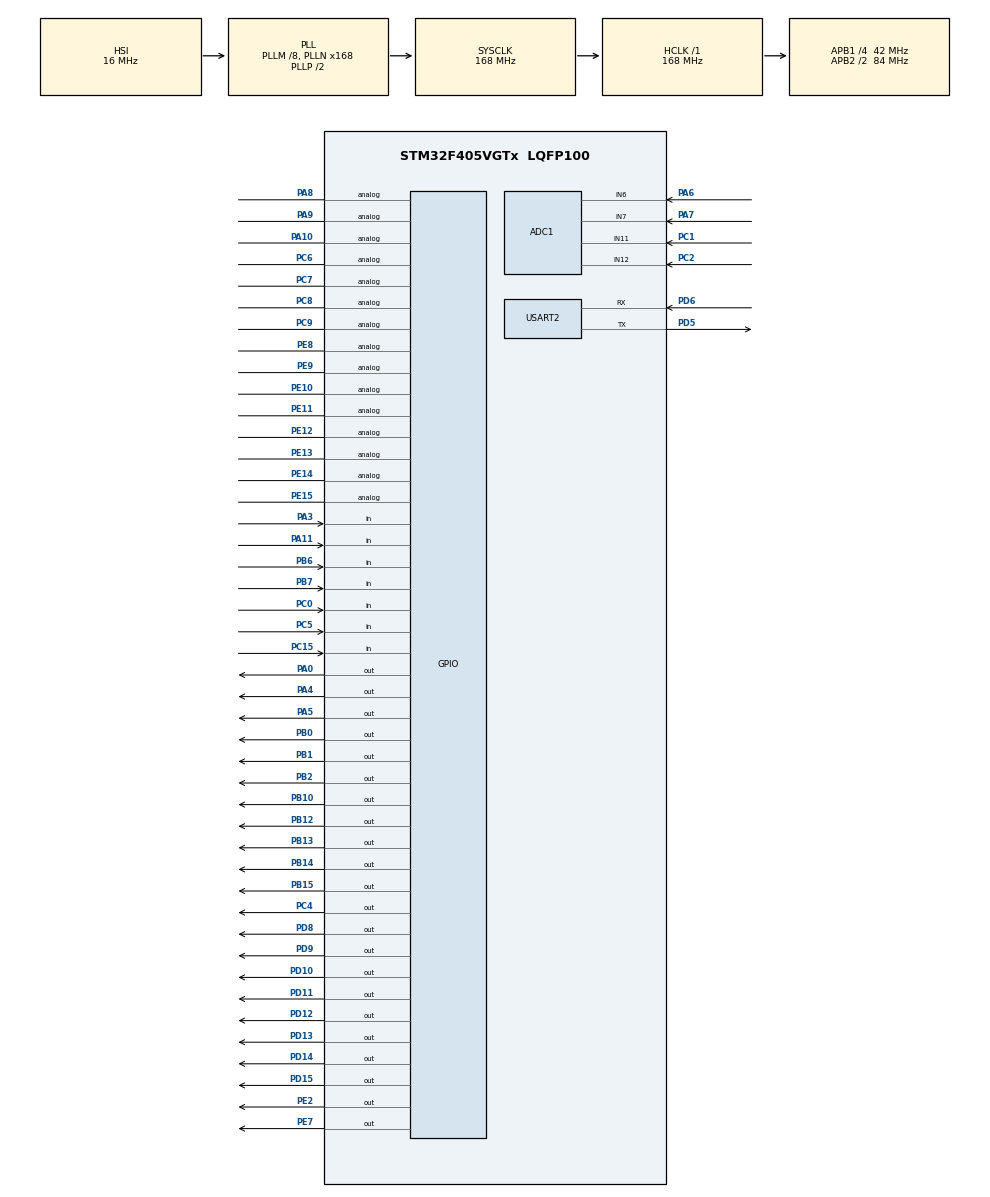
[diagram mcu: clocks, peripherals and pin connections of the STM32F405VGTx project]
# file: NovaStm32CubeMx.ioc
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ADC1.Channel-0\#ChannelRegularConversion=ADC_CHANNEL_11
ADC1.NbrOfConversionFlag=1
ADC1.Rank-0\#ChannelRegularConversion=1
ADC1.SamplingTime-0\#ChannelRegularConversion=ADC_SAMPLETIME_3CYCLES
ADC1.master=1
FREERTOS.Tasks01=defaultTask,24,128,StartDefaultTask,Default,NULL,Dynamic,NULL,NULL
FREERTOS.configENABLE_FPU=1
Mcu.Family=STM32F4
Mcu.Name=STM32F405VGTx
Mcu.Package=LQFP100
NVIC.PriorityGroup=NVIC_PRIORITYGROUP_4
PA0-WKUP.Signal=GPIO_Output
PA1.Signal=EVENTOUT
PA10.Signal=GPIO_Analog
PA11.Signal=GPIO_Input
PA13.Signal=SYS_JTMS-SWDIO
PA14.Signal=SYS_JTCK-SWCLK
PA2.Signal=EVENTOUT
PA3.Signal=GPIO_Input
PA4.Signal=GPIO_Output
PA5.Signal=GPIO_Output
PA6.Signal=ADCx_IN6
PA7.Signal=ADCx_IN7
PA8.Signal=GPIO_Analog
PA9.Signal=GPIO_Analog
PB0.Signal=GPIO_Output
PB1.Signal=GPIO_Output
PB10.Signal=GPIO_Output
PB12.Signal=GPIO_Output
PB13.Signal=GPIO_Output
PB14.Signal=GPIO_Output
PB15.Signal=GPIO_Output
PB2.Signal=GPIO_Output
PB6.Signal=GPIO_Input
PB7.Signal=GPIO_Input
PC0.Signal=GPIO_Input
PC1.Signal=ADCx_IN11
PC15-OSC32_OUT.Signal=GPIO_Input
PC2.Signal=ADCx_IN12
PC4.Signal=GPIO_Output
PC5.Signal=GPIO_Input
PC6.Signal=GPIO_Analog
PC7.Signal=GPIO_Analog
PC8.Signal=GPIO_Analog
PC9.Signal=GPIO_Analog
PD10.Signal=GPIO_Output
PD11.Signal=GPIO_Output
PD12.Signal=GPIO_Output
PD13.Signal=GPIO_Output
PD14.Signal=GPIO_Output
PD15.Signal=GPIO_Output
PD5.Mode=Asynchronous
PD5.Signal=USART2_TX
PD6.Mode=Asynchronous
PD6.Signal=USART2_RX
PD8.Signal=GPIO_Output
PD9.Signal=GPIO_Output
PE10.Signal=GPIO_Analog
PE11.Signal=GPIO_Analog
PE12.Signal=GPIO_Analog
PE13.Signal=GPIO_Analog
PE14.Signal=GPIO_Analog
PE15.Signal=GPIO_Analog
PE2.Signal=GPIO_Output
PE7.Signal=GPIO_Output
PE8.Signal=GPIO_Analog
PE9.Signal=GPIO_Analog
PH0-OSC_IN.Mode=HSE-External-Oscillator
PH0-OSC_IN.Signal=RCC_OSC_IN
PH1-OSC_OUT.Mode=HSE-External-Oscillator
PH1-OSC_OUT.Signal=RCC_OSC_OUT
ProjectManager.HeapSize=0x200
ProjectManager.StackSize=0x400
ProjectManager.TargetToolchain=MDK-ARM V5.27
RCC.48MHZClocksFreq_Value=84000000
RCC.AHBFreq_Value=168000000
RCC.APB1CLKDivider=RCC_HCLK_DIV4
RCC.APB1Freq_Value=42000000
RCC.APB1TimFreq_Value=84000000
RCC.APB2CLKDivider=RCC_HCLK_DIV2
RCC.APB2Freq_Value=84000000
RCC.APB2TimFreq_Value=168000000
RCC.CortexFreq_Value=168000000
RCC.HCLKFreq_Value=168000000
RCC.HSE_VALUE=8000000
RCC.HSI_VALUE=16000000
RCC.LSE_VALUE=32768
RCC.PLLM=8
RCC.PLLN=168
RCC.SYSCLKFreq_VALUE=168000000
RCC.SYSCLKSource=RCC_SYSCLKSOURCE_PLLCLK
RCC.VCOOutputFreq_Value=336000000
SH.ADCx_IN11.0=ADC1_IN11,IN11
SH.ADCx_IN12.0=ADC1_IN12,IN12
SH.ADCx_IN6.0=ADC1_IN6,IN6
SH.ADCx_IN7.0=ADC1_IN7,IN7
USART2.VirtualMode=VM_ASYNC
VP_FREERTOS_VS_CMSIS_V2.Mode=CMSIS_V2
VP_IWDG_VS_IWDG.Mode=IWDG_Activate
board=custom

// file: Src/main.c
/* USER CODE BEGIN Header */
/**
  ******************************************************************************
  * @file           : main.c
  * @brief          : Main program body
  ******************************************************************************
  * @attention
  *
  * <h2><center>&copy; Copyright (c) 2020 STMicroelectronics.
  * All rights reserved.</center></h2>
  *
  * This software component is licensed by ST under BSD 3-Clause license,
  * the "License"; You may not use this file except in compliance with the
  * License. You may obtain a copy of the License at:
  *                        opensource.org/licenses/BSD-3-Clause
  *
  ******************************************************************************
  */
/* USER CODE END Header */

#include "main.h"
#include "cmsis_os.h"
#include "FreeRTOS.h"
#include "Timers.h"
#include "..\MDK-ARM\delay.h"
#include "..\MDK-ARM\24cxx.h"
#include "..\MDK-ARM\keys.h"
#include "..\MDK-ARM\LCD_Display.h"
#include "..\MDK-ARM\userinterface.h"
#include "..\MDK-ARM\PWM.h"
#include "..\MDK-ARM\data.h"
#include "..\MDK-ARM\pwm_timer.h"
#include "..\MDK-ARM\ADCSample.h"
#include "..\MDK-ARM\uart2.h"
#include "stdio.h"
//#include "..\MDK-ARM\font.h"
//#include "..\MDK-ARM\powerON.h"

//typedef StaticTimer_t osStaticTimerDef_t;

/* USER CODE BEGIN PM */
#define STYTESM_POWER_ON HAL_GPIO_WritePin(GPIOA, GPIO_PIN_5, GPIO_PIN_SET)

/* USER CODE END PM */

ADC_HandleTypeDef hadc1;

IWDG_HandleTypeDef hiwdg;

/* Definitions for defaultTask */
osThreadId_t mainTaskTaskHandle;
const osThreadAttr_t mainTask_attributes = {
  .name = "MainTask",
  .priority = (osPriority_t) osPriorityNormal,
  .stack_size = 128 * 4
};

osThreadId_t keyScanTaskTaskHandle;
const osThreadAttr_t keyScanTask_attributes = {
  .name = "keyScanTask",
  .priority = (osPriority_t) osPriorityRealtime,
  .stack_size = 128 * 4
};

/* USER CODE END PV */

void SystemClock_Config(void);
static void MX_GPIO_Init(void);
static void MX_ADC1_Init(void);
static void MX_IWDG_Init(void);
void MainTask(void *argument);
void keyScanTask(void *argument);

u16 ADC_data = 0;
int main(void)
{
    /* MCU Configuration--------------------------------------------------------*/

    /* Reset of all peripherals, Initializes the Flash interface and the Systick. */
    HAL_Init();
    /* Configure the system clock */
    SystemClock_Config();

    /*delay time init */
    //delay_init(168);

    /* Initialize all configured peripherals */
    MX_GPIO_Init();
    HAL_GPIO_WritePin(GPIOD, GPIO_PIN_15, GPIO_PIN_SET);//GPIO_PIN_RESET); Kavo Logo Led
    LED_init(LED_ON);
    LED_control(GREEN_LED);
    for(u16 i = 0;i<1000;i++)
        delay_1_ms();
    STYTESM_POWER_ON;
    //for(u16 i = 0;i<2000;i++)
    //    delay_1_ms();
    LCD_Init();
    LCD_Clear(0XFFFF);
    LCD_BK_1;
    powerOn_displayFunc();

    LED_control(ORANGE_LED);
    LED_init(LED_ON);

    MX_ADC1_Init();
    IIC_Init();
    Keys_Init();
//    LCD_Init();
    PWM_Init();
#if DEBUG_ON
    MX_USART2_UART_Init();
#endif
    for(u16 i = 0;i<1000;i++)
        delay_1_ms();

    LED_control(BLUE_LED);
    for(u16 i = 0;i<2000;i++)
        delay_1_ms();

    //test_get_set_sys_para();
    //fagctory_default_store();
    //ADC_data = AT24CXX_ReadOneByte(4096);
    //EraseAll();
    check_para_is_valid();
    system_para_restore();
    //test_para_store_restore();
    //test_set_get_exposetime();
    //pictureDisplay(20,31,105,30,gImage_kV);
#if 0
    LCD_Clear(0X2965);
    LCD_Clear(0X528A);
    LCD_Clear(0X738E);
    LCD_Clear(0X8C51);
    LCD_Clear(0XBDF7);
    LCD_Clear(0XCE79);
    LCD_Clear(0XE73C);
#endif
//    LCD_Clear(0XFFFF);
//    LCD_BK_1;
//    powerOn_displayFunc();
    LED_init(LED_OFF);
    MainWindowDisplayFunc();

    LED_Control(tooth_position,LED_ON);

    while(HAL_GPIO_ReadPin(GPIOA, GPIO_PIN_11) == 0);//wait for the power key releasing

#if DEBUG_ON

#else
    MX_IWDG_Init();
#endif
    LED_control(GREEN_LED);

    //save the event: power on
    event_Data_Store(POWER_ON);

    //MainWindowDisplayFunc();
    //pictureDisplay(217+15,60,19,30 ,battery4);

   //  test_Event_Data_EEPROM_function();

   //set_voltage_current(1274, 1274);

   get_voltage_current(&pwm_voltage_cali,&pwm_current);
  //Keys_Portinit();
  //Keys_GetPins();
  //test
  //test_read_write_bytes();
  //AT24CXX_Check();

 // pwmSet(PWM_KV_REF, PWM_VOLTAGE_VALUE);
 // pwmSet(PWM_MA_REF, PWM_CURRENT_VALUE);
 // while(1);
 //  while(1)
 // {
 //     ADC_data = Get_Adc(BATTERY_VOLTAGE);
      // AT24CXX_Check();
      //AT24CXX_ReadOneByte(255);
      //test_time();
      //AT24CXX_ReadOneByte(0xAA);
      //test_read_write();
      //delay_us(100);
      //delay_1_ms();
      //delay_1_ms();
      //delay_1_ms();
      //ADC_data = Get_Adc(ADAPTER_VOLTAGE);
      //delay_1_ms();
      //delay_1_ms();
      //delay_1_ms();
      //Keys_Scan();
  //}

  /* Init scheduler */
  system_state = IDLE_STATE;
  WIN = MainWindowDisplay;
  osKernelInitialize();

  /* Create the timer(s) */
  /* creation of myTimer01 */
  //myTimer01Handle = osTimerNew(Callback01, osTimerOnce, NULL, &myTimer01_attributes);
  myTimer02Handle = osTimerNew(Callback02, osTimerPeriodic, NULL, &myTimer02_attributes);

  /* USER CODE BEGIN RTOS_TIMERS */
  /* start timers, add new ones, ... */
  osTimerStart(myTimer02Handle,1);//start timer2, peroid 1 ms
  /* USER CODE END RTOS_TIMERS */

  /* Create the thread(s) */
  /* creation of defaultTask */
  mainTaskTaskHandle = osThreadNew(MainTask, NULL, &mainTask_attributes);
  keyScanTaskTaskHandle = osThreadNew(keyScanTask,NULL,&keyScanTask_attributes);

  /* Start scheduler */
  osKernelStart();

  /* We should never get here as control is now taken by the scheduler */
  /* Infinite loop */
  while (1)
  {

  }
}

void SystemClock_Config(void)
{
  RCC_OscInitTypeDef RCC_OscInitStruct = {0};
  RCC_ClkInitTypeDef RCC_ClkInitStruct = {0};

  /** Configure the main internal regulator output voltage
  */
  __HAL_RCC_PWR_CLK_ENABLE();
  __HAL_PWR_VOLTAGESCALING_CONFIG(PWR_REGULATOR_VOLTAGE_SCALE1);
  /** Initializes the CPU, AHB and APB busses clocks
  */
  RCC_OscInitStruct.OscillatorType = RCC_OSCILLATORTYPE_HSI|RCC_OSCILLATORTYPE_LSI;
  RCC_OscInitStruct.HSIState = RCC_HSI_ON;
  RCC_OscInitStruct.HSICalibrationValue = RCC_HSICALIBRATION_DEFAULT;
  RCC_OscInitStruct.LSIState = RCC_LSI_ON;
  RCC_OscInitStruct.PLL.PLLState = RCC_PLL_ON;
  RCC_OscInitStruct.PLL.PLLSource = RCC_PLLSOURCE_HSI;
  RCC_OscInitStruct.PLL.PLLM = 8;
  RCC_OscInitStruct.PLL.PLLN = 168;
  RCC_OscInitStruct.PLL.PLLP = RCC_PLLP_DIV2;
  RCC_OscInitStruct.PLL.PLLQ = 4;
  if (HAL_RCC_OscConfig(&RCC_OscInitStruct) != HAL_OK)
  {
    Error_Handler();
  }
  /** Initializes the CPU, AHB and APB busses clocks
  */
  RCC_ClkInitStruct.ClockType = RCC_CLOCKTYPE_HCLK|RCC_CLOCKTYPE_SYSCLK
                              |RCC_CLOCKTYPE_PCLK1|RCC_CLOCKTYPE_PCLK2;
  RCC_ClkInitStruct.SYSCLKSource = RCC_SYSCLKSOURCE_PLLCLK;
  RCC_ClkInitStruct.AHBCLKDivider = RCC_SYSCLK_DIV1;
  RCC_ClkInitStruct.APB1CLKDivider = RCC_HCLK_DIV4;
  RCC_ClkInitStruct.APB2CLKDivider = RCC_HCLK_DIV2;

  if (HAL_RCC_ClockConfig(&RCC_ClkInitStruct, FLASH_LATENCY_5) != HAL_OK)
  {
    Error_Handler();
  }
}

static void MX_ADC1_Init(void)
{

//  ADC_ChannelConfTypeDef sConfig = {0};

  /** Configure the global features of the ADC (Clock, Resolution, Data Alignment and number of conversion)
  */
  hadc1.Instance = ADC1;
  hadc1.Init.ClockPrescaler = ADC_CLOCK_SYNC_PCLK_DIV4;
  hadc1.Init.Resolution = ADC_RESOLUTION_12B;
  hadc1.Init.ScanConvMode = DISABLE;
  hadc1.Init.ContinuousConvMode = DISABLE;
  hadc1.Init.DiscontinuousConvMode = DISABLE;
  hadc1.Init.ExternalTrigConvEdge = ADC_EXTERNALTRIGCONVEDGE_NONE;
  hadc1.Init.ExternalTrigConv = ADC_SOFTWARE_START;
  hadc1.Init.DataAlign = ADC_DATAALIGN_RIGHT;
  hadc1.Init.NbrOfConversion = 1;
  hadc1.Init.DMAContinuousRequests = DISABLE;
  hadc1.Init.EOCSelection = ADC_EOC_SINGLE_CONV;
  if (HAL_ADC_Init(&hadc1) != HAL_OK)
  {
    Error_Handler();
  }
  /** Configure for the selected ADC regular channel its corresponding rank in the sequencer and its sample time.
  */
#if 0
  sConfig.Channel = ADC_CHANNEL_11;
  sConfig.Rank = 1;
  sConfig.SamplingTime = ADC_SAMPLETIME_3CYCLES;
  if (HAL_ADC_ConfigChannel(&hadc1, &sConfig) != HAL_OK)
  {
    Error_Handler();
  }
#endif

}

static void MX_IWDG_Init(void)
{

  hiwdg.Instance = IWDG;
  hiwdg.Init.Prescaler = IWDG_PRESCALER_4;
  hiwdg.Init.Reload = 4095;
  if (HAL_IWDG_Init(&hiwdg) != HAL_OK)
  {
    Error_Handler();
  }

}

static void MX_GPIO_Init(void)
{
  GPIO_InitTypeDef GPIO_InitStruct = {0};

  /* GPIO Ports Clock Enable */
  __HAL_RCC_GPIOE_CLK_ENABLE();
  __HAL_RCC_GPIOC_CLK_ENABLE();
  __HAL_RCC_GPIOH_CLK_ENABLE();
  __HAL_RCC_GPIOA_CLK_ENABLE();
  __HAL_RCC_GPIOB_CLK_ENABLE();
  __HAL_RCC_GPIOD_CLK_ENABLE();

  /*Configure GPIO pin Output Level */
  HAL_GPIO_WritePin(GPIOE, GPIO_PIN_2|GPIO_PIN_7, GPIO_PIN_RESET);

  /*Configure GPIO pin Output Level */
  //PA0: 曝光使能，高有效，初始化为低
  //PA4:
  //PA5:
  HAL_GPIO_WritePin(GPIOA, GPIO_PIN_4, GPIO_PIN_SET);

  /*Configure GPIO pin Output Level */
  //LCD backlight
  HAL_GPIO_WritePin(GPIOC, GPIO_PIN_4, GPIO_PIN_RESET);

  /*Configure GPIO pin Output Level */
  //PB0: LCD RESET   PB10: LCD CS  PB14: LED 8
  //PB1: LCD RD      PB12: LED 10  PB15: LED 7
  //PB2: LCD WR      PB13: LED 9
  HAL_GPIO_WritePin(GPIOB, GPIO_PIN_0|GPIO_PIN_1|GPIO_PIN_2|GPIO_PIN_10
                          |GPIO_PIN_12|GPIO_PIN_13|GPIO_PIN_14|GPIO_PIN_15, GPIO_PIN_RESET);

  /*Configure GPIO pin Output Level */
  //PD8: LED 3     PD9:  LED 4      PD10: LED 5         PD11: LED 6
  //PD12: LED BLUE PD13：LED GREEN  PD14: LED ORGANGE   PD15：LED power
  HAL_GPIO_WritePin(GPIOD, GPIO_PIN_8|GPIO_PIN_9|GPIO_PIN_10|GPIO_PIN_11
                          |GPIO_PIN_12|GPIO_PIN_13|GPIO_PIN_14|GPIO_PIN_15, GPIO_PIN_RESET);

  /*Configure GPIO pins : PE2 buzzer*/
  GPIO_InitStruct.Pin = GPIO_PIN_2;
  GPIO_InitStruct.Mode = GPIO_MODE_OUTPUT_PP;
  GPIO_InitStruct.Pull = GPIO_NOPULL;
  GPIO_InitStruct.Speed = GPIO_SPEED_FREQ_LOW;
  HAL_GPIO_Init(GPIOE, &GPIO_InitStruct);

  /*Configure GPIO pins : PC15 PC0 PC5 */
  //PC0: 输任为低，表示过热
  //PC15: protect CPU
  GPIO_InitStruct.Pin = GPIO_PIN_15|GPIO_PIN_0;
  GPIO_InitStruct.Mode = GPIO_MODE_INPUT;
  GPIO_InitStruct.Pull = GPIO_NOPULL;
  HAL_GPIO_Init(GPIOC, &GPIO_InitStruct);

  /*Configure GPIO pins : PA0 PA4 PA5 */
  GPIO_InitStruct.Pin = GPIO_PIN_0|GPIO_PIN_4|GPIO_PIN_5;
  GPIO_InitStruct.Mode = GPIO_MODE_OUTPUT_PP;
  GPIO_InitStruct.Pull = GPIO_NOPULL;
  GPIO_InitStruct.Speed = GPIO_SPEED_FREQ_LOW;
  HAL_GPIO_Init(GPIOA, &GPIO_InitStruct);

  /*Configure GPIO pins : PB0 PB1 PB2
                           PB12 PB13 PB14 PB15 */
  GPIO_InitStruct.Pin = GPIO_PIN_12|GPIO_PIN_13|GPIO_PIN_14|GPIO_PIN_15;
  GPIO_InitStruct.Mode = GPIO_MODE_OUTPUT_PP;
  GPIO_InitStruct.Pull = GPIO_NOPULL;
  GPIO_InitStruct.Speed = GPIO_SPEED_FREQ_LOW;
  HAL_GPIO_Init(GPIOB, &GPIO_InitStruct);

  /*Configure GPIO pins : PD8 PD9 PD10 PD11
                           PD12 PD13 PD14 PD15 */
  GPIO_InitStruct.Pin = GPIO_PIN_8|GPIO_PIN_9|GPIO_PIN_10|GPIO_PIN_11
                          |GPIO_PIN_12|GPIO_PIN_13|GPIO_PIN_14|GPIO_PIN_15;
  GPIO_InitStruct.Mode = GPIO_MODE_OUTPUT_PP;
  GPIO_InitStruct.Pull = GPIO_NOPULL;
  GPIO_InitStruct.Speed = GPIO_SPEED_FREQ_LOW;
  HAL_GPIO_Init(GPIOD, &GPIO_InitStruct);

}

void MainTask(void *argument)
{
  /* USER CODE BEGIN 5 */
  /* Infinite loop */

  for(;;)
  {
    UserInterface();
    __HAL_IWDG_RELOAD_COUNTER(&hiwdg);

    osDelay(10);
  }
  /* USER CODE END 5 */
}

//static u8 data[7] = {0x55,0xAA,0x55,0xAA};
void keyScanTask(void *argument)
{
      /* USER CODE BEGIN 5 */
  /* Infinite loop */
  for(;;)
  {
    Keys_Scan();
    __HAL_IWDG_RELOAD_COUNTER(&hiwdg);
//    put_char(168);
//    data[0] = ' ';
//    sprintf(data,"active\n");
//    put_data(data,7);
//    test_uart2();
    osDelay(10);
  }
  /* USER CODE END 5 */
}

void Error_Handler(void)
{
}

/************************ (C) COPYRIGHT STMicroelectronics *****END OF FILE****/
